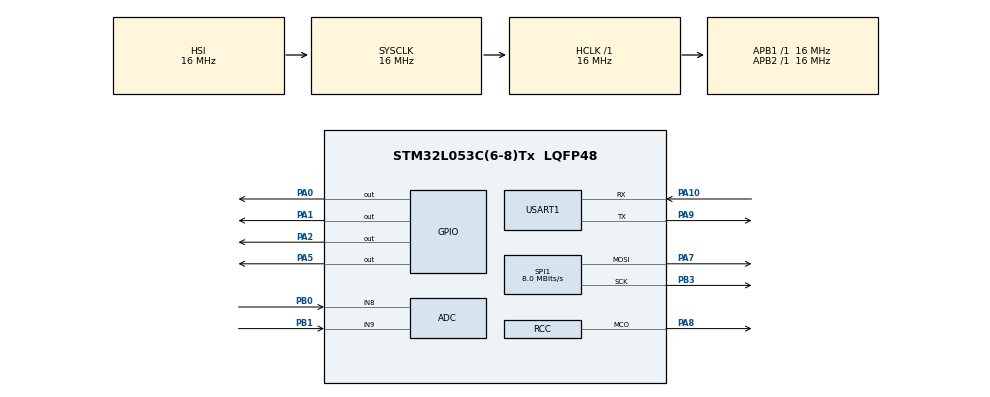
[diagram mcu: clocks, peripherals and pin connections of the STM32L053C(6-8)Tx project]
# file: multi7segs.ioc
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Mcu.Family=STM32L0
Mcu.Name=STM32L053C(6-8)Tx
Mcu.Package=LQFP48
PA0.Signal=GPIO_Output
PA1.Signal=GPIO_Output
PA10.Mode=Asynchronous
PA10.Signal=USART1_RX
PA13.Mode=Serial_Wire
PA13.Signal=SYS_SWDIO
PA14.Mode=Serial_Wire
PA14.Signal=SYS_SWCLK
PA2.Signal=GPIO_Output
PA5.Signal=GPIO_Output
PA7.Mode=TX_Only_Simplex_Unidirect_Master
PA7.Signal=SPI1_MOSI
PA8.Mode=Clock-out
PA8.Signal=RCC_MCO
PA9.Mode=Asynchronous
PA9.Signal=USART1_TX
PB0.Mode=IN8
PB0.Signal=ADC_IN8
PB1.Mode=IN9
PB1.Signal=ADC_IN9
PB3.Mode=TX_Only_Simplex_Unidirect_Master
PB3.Signal=SPI1_SCK
PC14-OSC32_IN.Mode=LSE-External-Oscillator
PC14-OSC32_IN.Signal=RCC_OSC32_IN
PC15-OSC32_OUT.Mode=LSE-External-Oscillator
PC15-OSC32_OUT.Signal=RCC_OSC32_OUT
ProjectManager.HeapSize=0x200
ProjectManager.StackSize=0x400
ProjectManager.TargetToolchain=SW4STM32
RCC.AHBFreq_Value=16000000
RCC.APB1Freq_Value=16000000
RCC.APB1TimFreq_Value=16000000
RCC.APB2Freq_Value=16000000
RCC.APB2TimFreq_Value=16000000
RCC.HCLKFreq_Value=16000000
RCC.HSE_VALUE=8000000
RCC.HSI16_VALUE=16000000
RCC.HSI48MClockSelection=RCC_USBCLKSOURCE_HSI48
RCC.HSI48_VALUE=48000000
RCC.HSI_VALUE=16000000
RCC.MSI_VALUE=2097000
RCC.RCC_MCOSource=RCC_MCO1SOURCE_HSI
RCC.RTCClockSelection=RCC_RTCCLKSOURCE_LSE
RCC.RTCClockSelectionVirtual=RCC_RTCCLKSOURCE_LSE
RCC.SYSCLKFreq_VALUE=16000000
RCC.SYSCLKSource=RCC_SYSCLKSOURCE_HSI
RCC.VCOOutputFreq_Value=48000000
SPI1.CalculateBaudRate=8.0 MBits/s
SPI1.Mode=SPI_MODE_MASTER
VP_ADC_TempSens_Input.Mode=IN-TempSens
VP_RNG_VS_RNG.Mode=RNG_Activate
VP_RTC_VS_RTC_Activate.Mode=RTC_Enabled
board=multi7segs

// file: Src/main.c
/**
  ******************************************************************************
  * File Name          : main.c
  * Description        : Main program body
  ******************************************************************************
  *
  * COPYRIGHT(c) 2017 STMicroelectronics
  *
  * Redistribution and use in source and binary forms, with or without modification,
  * are permitted provided that the following conditions are met:
  *   1. Redistributions of source code must retain the above copyright notice,
  *      this list of conditions and the following disclaimer.
  *   2. Redistributions in binary form must reproduce the above copyright notice,
  *      this list of conditions and the following disclaimer in the documentation
  *      and/or other materials provided with the distribution.
  *   3. Neither the name of STMicroelectronics nor the names of its contributors
  *      may be used to endorse or promote products derived from this software
  *      without specific prior written permission.
  *
  * THIS SOFTWARE IS PROVIDED BY THE COPYRIGHT HOLDERS AND CONTRIBUTORS "AS IS"
  * AND ANY EXPRESS OR IMPLIED WARRANTIES, INCLUDING, BUT NOT LIMITED TO, THE
  * IMPLIED WARRANTIES OF MERCHANTABILITY AND FITNESS FOR A PARTICULAR PURPOSE ARE
  * DISCLAIMED. IN NO EVENT SHALL THE COPYRIGHT HOLDER OR CONTRIBUTORS BE LIABLE
  * FOR ANY DIRECT, INDIRECT, INCIDENTAL, SPECIAL, EXEMPLARY, OR CONSEQUENTIAL
  * DAMAGES (INCLUDING, BUT NOT LIMITED TO, PROCUREMENT OF SUBSTITUTE GOODS OR
  * SERVICES; LOSS OF USE, DATA, OR PROFITS; OR BUSINESS INTERRUPTION) HOWEVER
  * CAUSED AND ON ANY THEORY OF LIABILITY, WHETHER IN CONTRACT, STRICT LIABILITY,
  * OR TORT (INCLUDING NEGLIGENCE OR OTHERWISE) ARISING IN ANY WAY OUT OF THE USE
  * OF THIS SOFTWARE, EVEN IF ADVISED OF THE POSSIBILITY OF SUCH DAMAGE.
  *
  ******************************************************************************
  */
#include "main.h"
#include "stm32l0xx_hal.h"
#include "adc.h"
#include "rtc.h"
#include "spi.h"
#include "usart.h"
#include "gpio.h"

/* USER CODE BEGIN PV */
/* Private variables ---------------------------------------------------------*/

/* USER CODE END PV */

void SystemClock_Config(void);
void Error_Handler(void);

/* USER CODE BEGIN PFP */
/* Private function prototypes -----------------------------------------------*/

/* USER CODE END PFP */

int main(void)
{

  /* MCU Configuration----------------------------------------------------------*/

  /* Reset of all peripherals, Initializes the Flash interface and the Systick. */
  HAL_Init();

  /* Configure the system clock */
  SystemClock_Config();

  /* Initialize all configured peripherals */
  MX_GPIO_Init();
  MX_ADC_Init();
  MX_RTC_Init();
  MX_SPI1_Init();
  MX_USART1_UART_Init();

  /* Infinite loop */
  while (1)
  {

  /* USER CODE BEGIN 3 */
	  HAL_GPIO_TogglePin(GPIOA, GPIO_PIN_5);
	  HAL_Delay(500);

  }
  /* USER CODE END 3 */

}

/** System Clock Configuration
*/
void SystemClock_Config(void)
{

  RCC_OscInitTypeDef RCC_OscInitStruct;
  RCC_ClkInitTypeDef RCC_ClkInitStruct;
  RCC_PeriphCLKInitTypeDef PeriphClkInit;

    /**Configure the main internal regulator output voltage
    */
  __HAL_PWR_VOLTAGESCALING_CONFIG(PWR_REGULATOR_VOLTAGE_SCALE1);

    /**Initializes the CPU, AHB and APB busses clocks
    */
  RCC_OscInitStruct.OscillatorType = RCC_OSCILLATORTYPE_HSI|RCC_OSCILLATORTYPE_LSE;
  RCC_OscInitStruct.LSEState = RCC_LSE_ON;
  RCC_OscInitStruct.HSIState = RCC_HSI_ON;
  RCC_OscInitStruct.HSICalibrationValue = 16;
  RCC_OscInitStruct.PLL.PLLState = RCC_PLL_NONE;
  if (HAL_RCC_OscConfig(&RCC_OscInitStruct) != HAL_OK)
  {
    Error_Handler();
  }

    /**Initializes the CPU, AHB and APB busses clocks
    */
  RCC_ClkInitStruct.ClockType = RCC_CLOCKTYPE_HCLK|RCC_CLOCKTYPE_SYSCLK
                              |RCC_CLOCKTYPE_PCLK1|RCC_CLOCKTYPE_PCLK2;
  RCC_ClkInitStruct.SYSCLKSource = RCC_SYSCLKSOURCE_HSI;
  RCC_ClkInitStruct.AHBCLKDivider = RCC_SYSCLK_DIV1;
  RCC_ClkInitStruct.APB1CLKDivider = RCC_HCLK_DIV1;
  RCC_ClkInitStruct.APB2CLKDivider = RCC_HCLK_DIV1;

  if (HAL_RCC_ClockConfig(&RCC_ClkInitStruct, FLASH_LATENCY_0) != HAL_OK)
  {
    Error_Handler();
  }

  PeriphClkInit.PeriphClockSelection = RCC_PERIPHCLK_USART1|RCC_PERIPHCLK_RTC;
  PeriphClkInit.Usart1ClockSelection = RCC_USART1CLKSOURCE_PCLK2;
  PeriphClkInit.RTCClockSelection = RCC_RTCCLKSOURCE_LSE;
  if (HAL_RCCEx_PeriphCLKConfig(&PeriphClkInit) != HAL_OK)
  {
    Error_Handler();
  }

  HAL_RCC_MCOConfig(RCC_MCO1, RCC_MCO1SOURCE_HSI, RCC_MCODIV_1);

    /**Configure LSE Drive Capability
    */
  __HAL_RCC_LSEDRIVE_CONFIG(RCC_LSEDRIVE_LOW);

    /**Configure the Systick interrupt time
    */
  HAL_SYSTICK_Config(HAL_RCC_GetHCLKFreq()/1000);

    /**Configure the Systick
    */
  HAL_SYSTICK_CLKSourceConfig(SYSTICK_CLKSOURCE_HCLK);

  /* SysTick_IRQn interrupt configuration */
  HAL_NVIC_SetPriority(SysTick_IRQn, 0, 0);
}

void Error_Handler(void)
{
  /* USER CODE BEGIN Error_Handler */
  /* User can add his own implementation to report the HAL error return state */
	HAL_GPIO_WritePin(GPIOA, GPIO_PIN_5, GPIO_PIN_SET);
  while(1)
  {
  }
  /* USER CODE END Error_Handler */
}

/************************ (C) COPYRIGHT STMicroelectronics *****END OF FILE****/
